VERSION "1.0"
NS_ :

BS_:

BU_: ECU

BO_ 1536 THROTTLE: 4 ECU
 SG_ THROTTLE_signal : 0|8@1+ (1,0) [0|255] ""  ECU

BO_ 1537 BRAKE: 4 ECU
 SG_ BRAKE_signal : 0|8@1+ (1,0) [0|255] ""  ECU

BO_ 1538 STEER: 4 ECU
 SG_ STEER_signal : 0|8@1+ (1,0) [0|255] ""  ECU

BO_ 1539 REVERSE: 1 ECU
 SG_ REVERSE_signal : 0|8@1+ (1,0) [0|255] ""  ECU

BO_ 1540 HAND_BRAKE: 1 ECU
 SG_ HAND_BRAKE_signal : 0|8@1+ (1,0) [0|255] ""  ECU

BO_ 1541 AUTOPILOT: 4 ECU
 SG_ AUTOPILOT_signal : 0|8@1+ (1,0) [0|255] ""  ECU

BO_ 1542 MANUAL_TRANSMISSION: 1 ECU
 SG_ MANUAL_TRANSMISSION_signal : 0|8@1+ (1,0) [0|255] ""  ECU

BO_ 1543 GEAR: 4 ECU
 SG_ GEAR_signal : 0|8@1+ (1,0) [0|255] ""  ECU

BO_ 1548 DOORS: 1 ECU
 SG_ DOORS_signal : 0|8@1+ (1,0) [0|255] ""  ECU

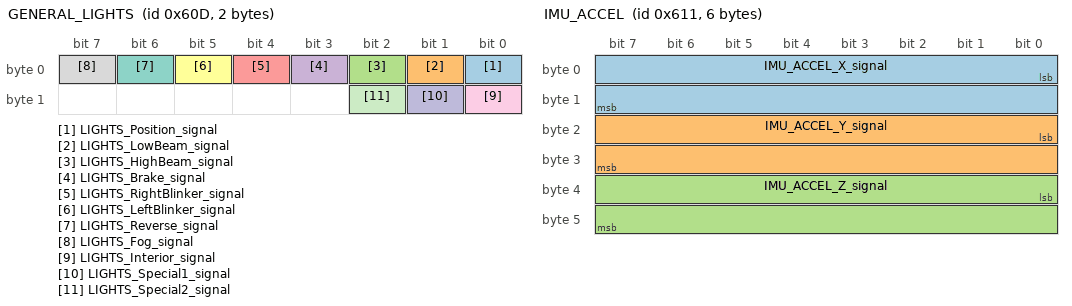
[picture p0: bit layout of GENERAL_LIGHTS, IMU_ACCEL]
BO_ 1549 GENERAL_LIGHTS: 2 ECU
 SG_ LIGHTS_Position_signal     : 0|1@1+  (1,0) [0|1] ""  ECU
 SG_ LIGHTS_LowBeam_signal      : 1|1@1+  (1,0) [0|1] ""  ECU
 SG_ LIGHTS_HighBeam_signal     : 2|1@1+  (1,0) [0|1] ""  ECU
 SG_ LIGHTS_Brake_signal        : 3|1@1+  (1,0) [0|1] ""  ECU
 SG_ LIGHTS_RightBlinker_signal : 4|1@1+  (1,0) [0|1] ""  ECU
 SG_ LIGHTS_LeftBlinker_signal  : 5|1@1+  (1,0) [0|1] ""  ECU
 SG_ LIGHTS_Reverse_signal      : 6|1@1+  (1,0) [0|1] ""  ECU
 SG_ LIGHTS_Fog_signal          : 7|1@1+  (1,0) [0|1] ""  ECU
 SG_ LIGHTS_Interior_signal     : 8|1@1+  (1,0) [0|1] ""  ECU
 SG_ LIGHTS_Special1_signal     : 9|1@1+  (1,0) [0|1] ""  ECU
 SG_ LIGHTS_Special2_signal     : 10|1@1+ (1,0) [0|1] ""  ECU

BO_ 1550 GNSS: 8 ECU
 SG_ GNSS_LAT_signal : 0|32@1- (0.0000001,0) [-90|90] "deg"  ECU
 SG_ GNSS_LON_signal : 32|32@1- (0.0000001,0) [-180|180] "deg"  ECU

BO_ 1551 COLLISION: 2 ECU
 SG_ COLLISION_INTENSITY_signal : 0|16@1+ (0.1,0) [0|6553.5] ""  ECU

BO_ 1552 LANE_INVASION: 2 ECU
 SG_ LANE_INVASION_TYPE_signal : 0|16@1+ (1,0) [0|65535] ""  ECU

BO_ 1553 IMU_ACCEL: 6 ECU
 SG_ IMU_ACCEL_X_signal : 0|16@1- (0.01,0) [-327.68|327.67] "m/s2"  ECU
 SG_ IMU_ACCEL_Y_signal : 16|16@1- (0.01,0) [-327.68|327.67] "m/s2"  ECU
 SG_ IMU_ACCEL_Z_signal : 32|16@1- (0.01,0) [-327.68|327.67] "m/s2"  ECU

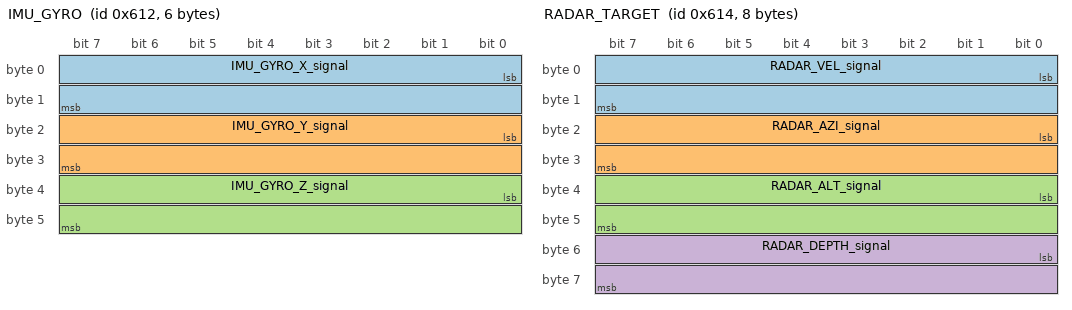
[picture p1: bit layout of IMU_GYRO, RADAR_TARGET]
BO_ 1554 IMU_GYRO: 6 ECU
 SG_ IMU_GYRO_X_signal : 0|16@1- (0.01,0) [-327.68|327.67] "deg/s"  ECU
 SG_ IMU_GYRO_Y_signal : 16|16@1- (0.01,0) [-327.68|327.67] "deg/s"  ECU
 SG_ IMU_GYRO_Z_signal : 32|16@1- (0.01,0) [-327.68|327.67] "deg/s"  ECU

BO_ 1555 IMU_COMPASS: 2 ECU
 SG_ IMU_COMPASS_signal : 0|16@1+ (0.01,0) [0|655.35] "deg"  ECU

BO_ 1556 RADAR_TARGET: 8 ECU
 SG_ RADAR_VEL_signal : 0|16@1- (0.01,0) [-327.68|327.67] "m/s"  ECU
 SG_ RADAR_AZI_signal : 16|16@1- (0.01,0) [-327.68|327.67] "deg"  ECU
 SG_ RADAR_ALT_signal : 32|16@1- (0.01,0) [-327.68|327.67] "deg"  ECU
 SG_ RADAR_DEPTH_signal : 48|16@1+ (0.01,0) [0|655.35] "m"  ECU

BO_ 1557 CAM_AUTOPILOT_ENABLE: 1 ECU
 SG_ CAM_AUTOPILOT_ENABLE_signal : 0|8@1+ (1,0) [0|255] ""  ECU

BA_DEF_ BO_ "GenMsgCycleTime" INT 0 10000;

BA_DEF_DEF_ "GenMsgCycleTime" 0;

BA_ "GenMsgCycleTime" BO_ 1536 100;
BA_ "GenMsgCycleTime" BO_ 1537 100;
BA_ "GenMsgCycleTime" BO_ 1538 100;
BA_ "GenMsgCycleTime" BO_ 1539 200;
BA_ "GenMsgCycleTime" BO_ 1540 200;
BA_ "GenMsgCycleTime" BO_ 1541 500;
BA_ "GenMsgCycleTime" BO_ 1542 500;
BA_ "GenMsgCycleTime" BO_ 1543 200;
BA_ "GenMsgCycleTime" BO_ 1550 1000;
BA_ "GenMsgCycleTime" BO_ 1553 100;
BA_ "GenMsgCycleTime" BO_ 1554 100;
BA_ "GenMsgCycleTime" BO_ 1555 100;
